# CIU32L051 register map
File version: 1.0.0
Registers are 32-bit, read-write, reset 0x0 unless marked. A register's access mark holds for its fields unless they carry their own. Offsets are from the block's base; [hi:lo] are bit positions; {n}, {i} and the like mark numbered series.

## EXTI
Base 0x40021800
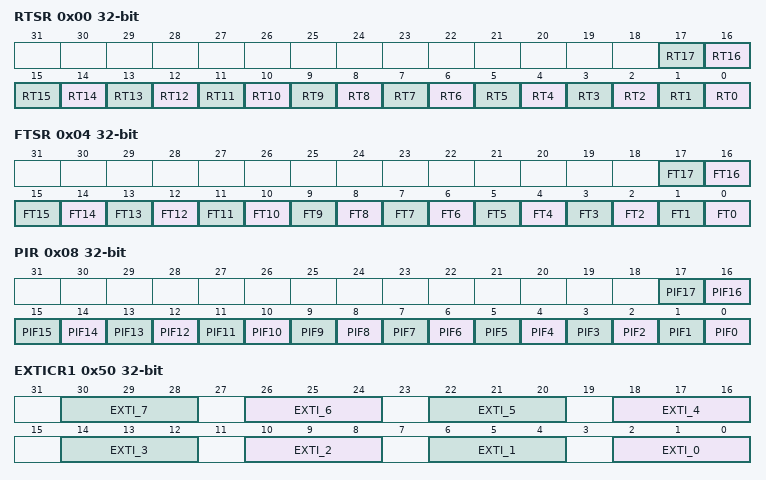
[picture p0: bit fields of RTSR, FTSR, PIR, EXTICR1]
0x00 RTSR
  [n] RT{n} (n=0..17)
0x04 FTSR
  [n] FT{n} (n=0..17)
0x08 PIR
  [n] PIF{n} (n=0..17)
0x50 EXTICR1
  [4n+2:4n] EXTI_{n} (n=0..7)
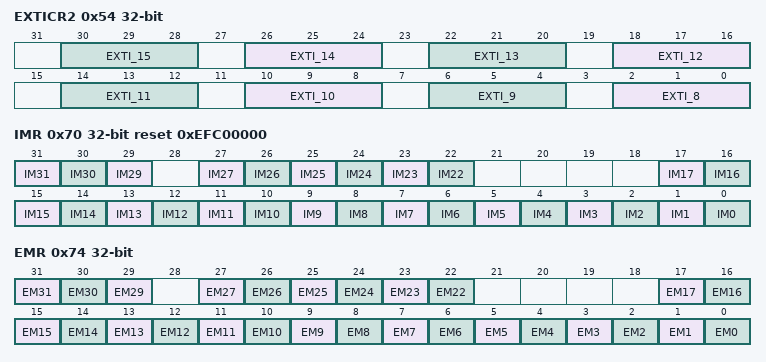
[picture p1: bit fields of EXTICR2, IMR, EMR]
0x54 EXTICR2
  [4n-30:4n-32] EXTI_{n} (n=8..15)
0x70 IMR reset 0xEFC00000
  [31] IM31, [30] IM30, [29] IM29, [n] IM{n} (n=22..27), [n] IM{n} (n=0..17)
0x74 EMR
  [31] EM31, [30] EM30, [29] EM29, [n] EM{n} (n=22..27), [n] EM{n} (n=0..17)

## FLASH
Base 0x40022000
0x00 ACR
  [1:0] LATENCY
0x08 CRKEY
0x0C OPTKEY
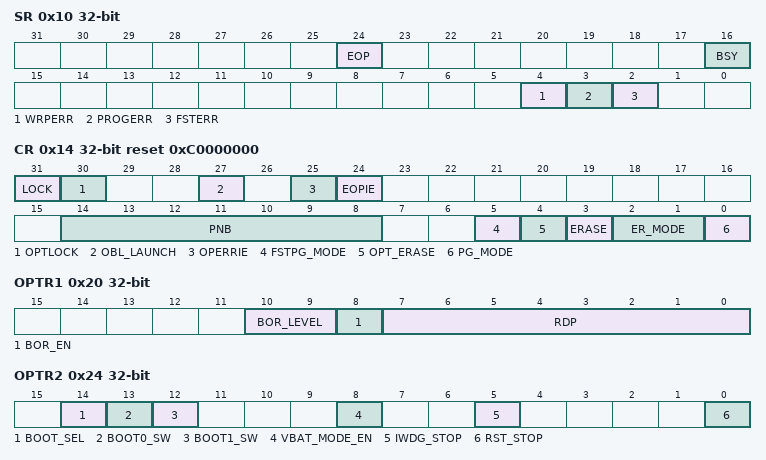
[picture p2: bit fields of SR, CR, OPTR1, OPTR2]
0x10 SR
  [24] EOP, [16] BSY, [4] WRPERR, [3] PROGERR, [2] FSTERR
0x14 CR reset 0xC0000000
  [31] LOCK, [30] OPTLOCK, [27] OBL_LAUNCH, [25] OPERRIE, [24] EOPIE, [14:8] PNB, [5] FSTPG_MODE, [4] OPT_ERASE, [3] ERASE, [2:1] ER_MODE, [0] PG_MODE
0x20 OPTR1
  [10:9] BOR_LEVEL, [8] BOR_EN, [7:0] RDP
0x24 OPTR2
  [14] BOOT_SEL, [13] BOOT0_SW, [12] BOOT1_SW, [8] VBAT_MODE_EN, [5] IWDG_STOP, [0] RST_STOP
0x38 WRP1AS
  [6:0] WRP1A_START
0x3C WRP1AE
  [6:0] WRP1A_END
0x40 WRP1BS
  [6:0] WRP1B_START
0x44 WRP1BE
  [6:0] WRP1B_END

## GPIOA
Base 0x50000000
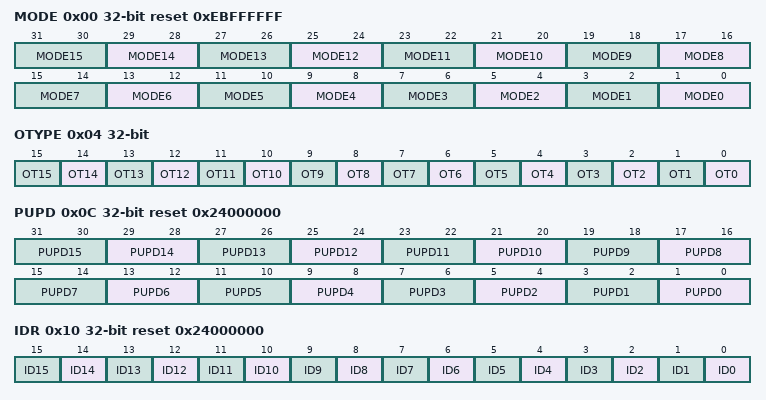
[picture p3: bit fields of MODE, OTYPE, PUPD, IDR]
0x00 MODE reset 0xEBFFFFFF
  [2n+1:2n] MODE{n} (n=0..15)
0x04 OTYPE
  [n] OT{n} (n=0..15)
0x0C PUPD reset 0x24000000
  [2n+1:2n] PUPD{n} (n=0..15)
0x10 IDR reset 0x24000000
  [n] ID{n} (n=0..15)
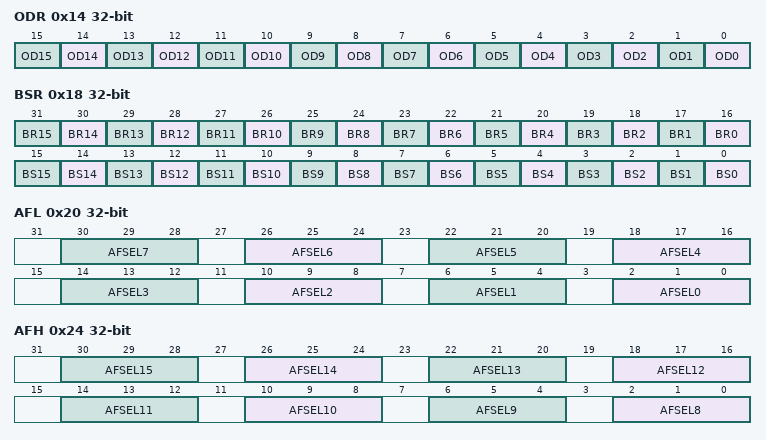
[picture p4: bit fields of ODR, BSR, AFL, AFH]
0x14 ODR
  [n] OD{n} (n=0..15)
0x18 BSR
  [n+16] BR{n} (n=0..15), [n] BS{n} (n=0..15)
0x20 AFL
  [4n+2:4n] AFSEL{n} (n=0..7)
0x24 AFH
  [4n-30:4n-32] AFSEL{n} (n=8..15)
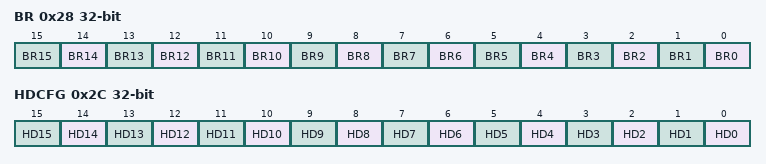
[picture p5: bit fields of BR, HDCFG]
0x28 BR
  [n] BR{n} (n=0..15)
0x2C HDCFG
  [n] HD{n} (n=0..15)

## GPIOB
Base 0x50000400
Registers as GPIOA, without HDCFG; these are added or differ:
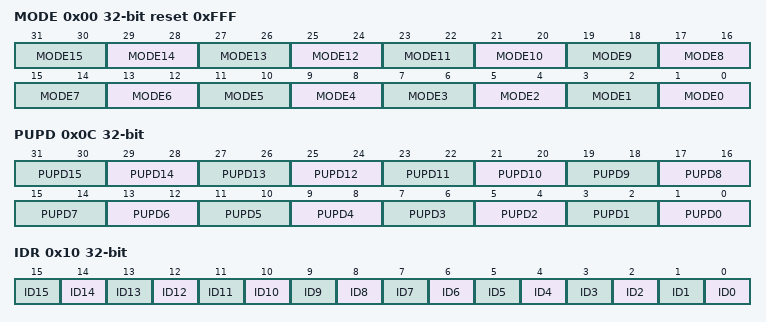
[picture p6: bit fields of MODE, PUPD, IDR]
0x00 MODE reset 0xFFF
  [2n+1:2n] MODE{n} (n=0..15)
0x0C PUPD
  [2n+1:2n] PUPD{n} (n=0..15)
0x10 IDR
  [n] ID{n} (n=0..15)

## GPIOC
Base 0x50000800
Registers as GPIOB; these are added or differ:
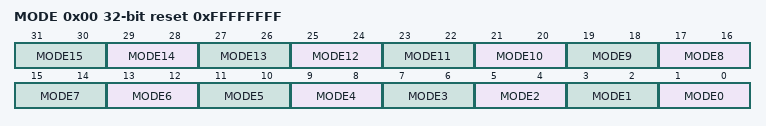
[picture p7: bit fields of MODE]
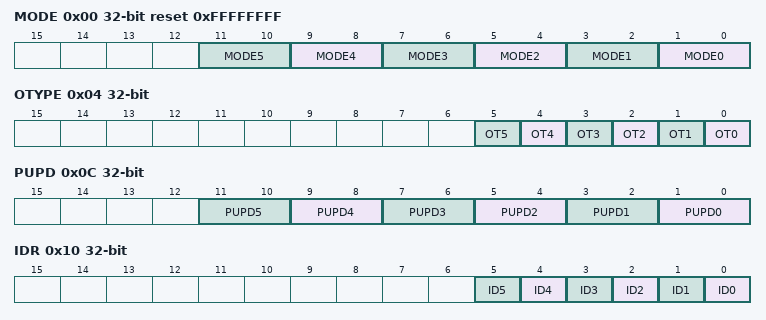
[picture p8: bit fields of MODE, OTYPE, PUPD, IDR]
0x00 MODE reset 0xFFFFFFFF
  [2n+1:2n] MODE{n} (n=0..15)

## GPIOD
Base 0x50000C00
0x00 MODE reset 0xFFFFFFFF
  [2n+1:2n] MODE{n} (n=0..5)
0x04 OTYPE
  [n] OT{n} (n=0..5)
0x0C PUPD
  [2n+1:2n] PUPD{n} (n=0..5)
0x10 IDR
  [n] ID{n} (n=0..5)
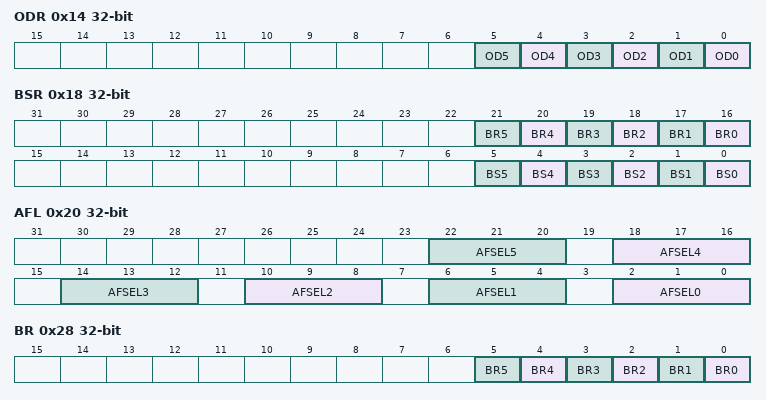
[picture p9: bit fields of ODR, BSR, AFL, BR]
0x14 ODR
  [n] OD{n} (n=0..5)
0x18 BSR
  [n+16] BR{n} (n=0..5), [n] BS{n} (n=0..5)
0x20 AFL
  [4n+2:4n] AFSEL{n} (n=0..5)
0x28 BR
  [n] BR{n} (n=0..5)
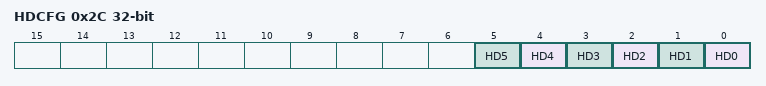
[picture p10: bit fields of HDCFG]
0x2C HDCFG
  [n] HD{n} (n=0..5)

## GPIOF
Base 0x50001400
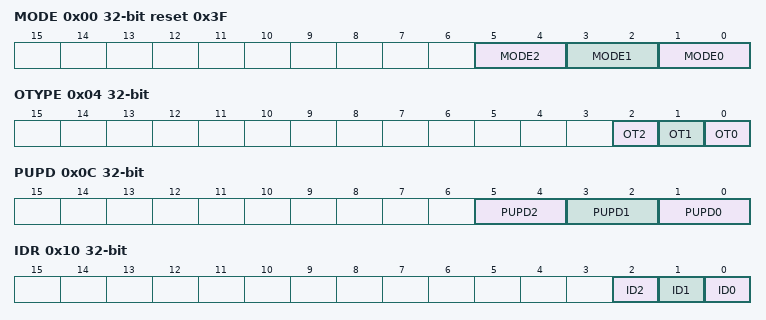
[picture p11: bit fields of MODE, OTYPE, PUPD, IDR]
0x00 MODE reset 0x3F
  [5:4] MODE2, [3:2] MODE1, [1:0] MODE0
0x04 OTYPE
  [2] OT2, [1] OT1, [0] OT0
0x0C PUPD
  [5:4] PUPD2, [3:2] PUPD1, [1:0] PUPD0
0x10 IDR
  [2] ID2, [1] ID1, [0] ID0
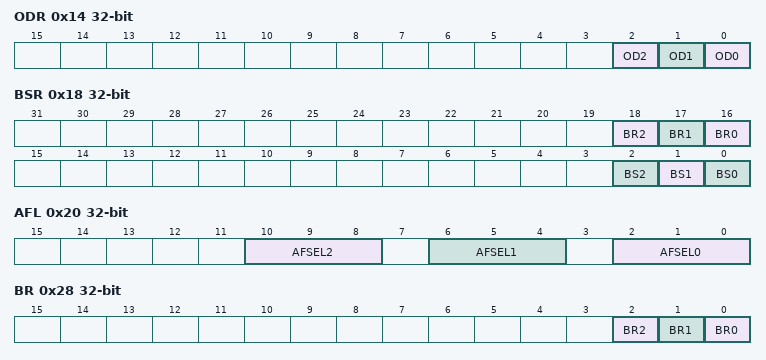
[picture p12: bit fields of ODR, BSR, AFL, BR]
0x14 ODR
  [2] OD2, [1] OD1, [0] OD0
0x18 BSR
  [18] BR2, [17] BR1, [16] BR0, [2] BS2, [1] BS1, [0] BS0
0x20 AFL
  [10:8] AFSEL2, [6:4] AFSEL1, [2:0] AFSEL0
0x28 BR
  [2] BR2, [1] BR1, [0] BR0

## I2C1
Base 0x40005400
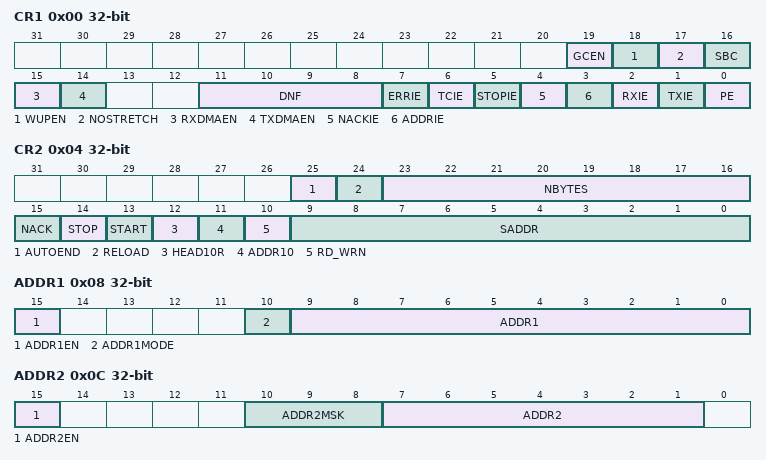
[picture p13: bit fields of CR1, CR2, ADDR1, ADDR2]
0x00 CR1
  [19] GCEN, [18] WUPEN, [17] NOSTRETCH, [16] SBC, [15] RXDMAEN, [14] TXDMAEN, [11:8] DNF, [7] ERRIE, [6] TCIE, [5] STOPIE, [4] NACKIE, [3] ADDRIE, [2] RXIE, [1] TXIE, [0] PE
0x04 CR2
  [25] AUTOEND, [24] RELOAD, [23:16] NBYTES, [15] NACK, [14] STOP, [13] START, [12] HEAD10R, [11] ADDR10, [10] RD_WRN, [9:0] SADDR
0x08 ADDR1
  [15] ADDR1EN, [10] ADDR1MODE, [9:0] ADDR1
0x0C ADDR2
  [15] ADDR2EN, [10:8] ADDR2MSK, [7:1] ADDR2
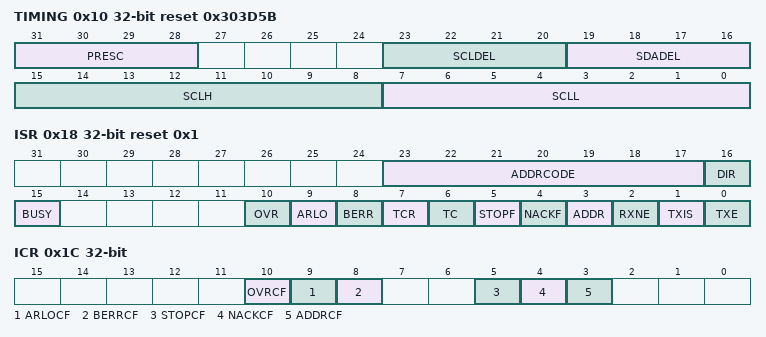
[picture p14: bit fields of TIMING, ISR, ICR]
0x10 TIMING reset 0x303D5B
  [31:28] PRESC, [23:20] SCLDEL, [19:16] SDADEL, [15:8] SCLH, [7:0] SCLL
0x18 ISR reset 0x1
  [23:17] ADDRCODE, [16] DIR, [15] BUSY, [10] OVR, [9] ARLO, [8] BERR, [7] TCR, [6] TC, [5] STOPF, [4] NACKF, [3] ADDR, [2] RXNE, [1] TXIS, [0] TXE
0x1C ICR
  [10] OVRCF, [9] ARLOCF, [8] BERRCF, [5] STOPCF, [4] NACKCF, [3] ADDRCF
0x24 RDR
  [7:0] RXDATA
0x28 TDR
  [7:0] TXDATA

## IWDG
Base 0x40003000
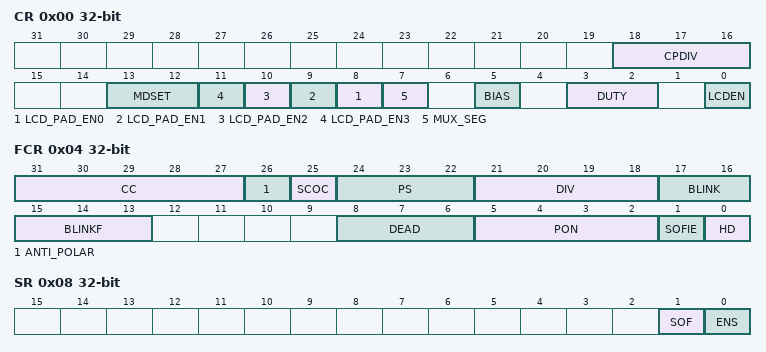
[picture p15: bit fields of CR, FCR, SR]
0x00 CR
  [15:0] KEY
0x04 CFG
  [2:0] OVP
0x10 WINR
  [11:0] WIN
0x14 CNT
  [11:0] CNT

## LCD
Base 0x40002400
0x00 CR
  [18:16] CPDIV, [13:12] MDSET, [n+8] LCD_PAD_EN{n} (n=0..3), [7] MUX_SEG, [5] BIAS, [3:2] DUTY, [0] LCDEN
0x04 FCR
  [31:27] CC, [26] ANTI_POLAR, [25] SCOC, [24:22] PS, [21:18] DIV, [17:16] BLINK, [15:13] BLINKF, [8:6] DEAD, [5:2] PON, [1] SOFIE, [0] HD
0x08 SR
  [1] SOF, [0] ENS
0x0C CLR
  [1] SOFC
0x14 RAM0
  [31:0] SEGMENT_DATA
0x18 RAM1 reset 0x1
  [31:0] SEGMENT_DATA
0x1C RAM2 reset 0x2
  [31:0] SEGMENT_DATA
0x20 RAM3 reset 0x3
  [31:0] SEGMENT_DATA
0x24 RAM4 reset 0x4
  [31:0] SEGMENT_DATA
0x28 RAM5 reset 0x5
  [31:0] SEGMENT_DATA
0x2C RAM6 reset 0x6
  [31:0] SEGMENT_DATA
0x30 RAM7 reset 0x7
  [31:0] SEGMENT_DATA
0x34 RAM8 reset 0x8
  [31:0] SEGMENT_DATA
0x38 RAM9 reset 0x9
  [31:0] SEGMENT_DATA
